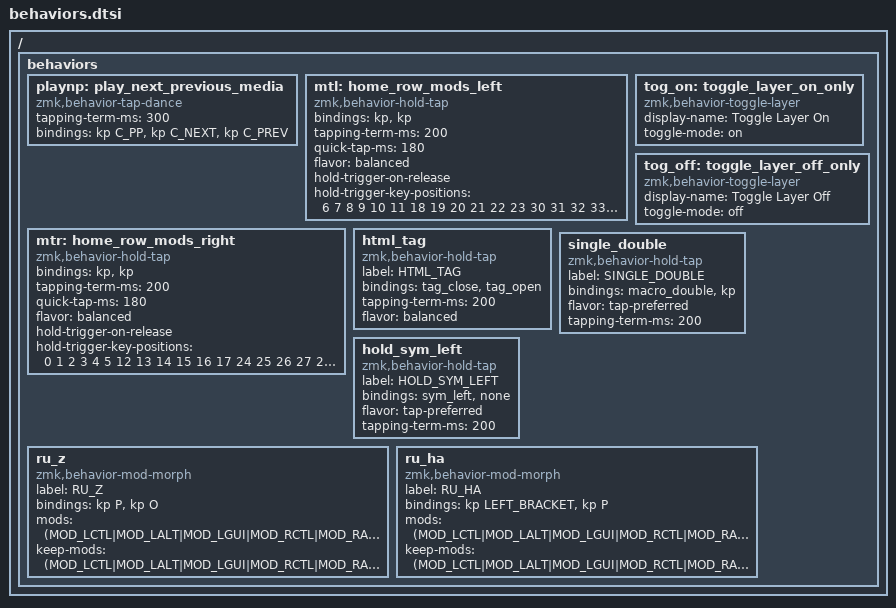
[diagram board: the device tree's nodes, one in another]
/ {
  behaviors {

    playnp: play_next_previous_media {
        compatible = "zmk,behavior-tap-dance";
        #binding-cells = <0>;
        tapping-term-ms = <300>;
        bindings = <&kp C_PP>, <&kp C_NEXT>, <&kp C_PREV>;
    };

    mtl: home_row_mods_left {
        compatible = "zmk,behavior-hold-tap";
        bindings = <&kp>, <&kp>;

        #binding-cells = <2>;
        tapping-term-ms = <200>;
        quick-tap-ms = <180>;
        flavor = "balanced";
        hold-trigger-on-release;
        hold-trigger-key-positions = <6 7 8 9 10 11 18 19 20 21 22 23 30 31 32 33 34 35 40 41 39 38 37 36 12 24>;
    };

    mtr: home_row_mods_right {
        compatible = "zmk,behavior-hold-tap";
        bindings = <&kp>, <&kp>;

        #binding-cells = <2>;
        tapping-term-ms = <200>;
        quick-tap-ms = <180>;
        flavor = "balanced";
        hold-trigger-on-release;
        hold-trigger-key-positions = <0 1 2 3 4 5 12 13 14 15 16 17 24 25 26 27 28 29 36 37 38 39 40 41>;
    };

    tog_on: toggle_layer_on_only {
        compatible = "zmk,behavior-toggle-layer";
        #binding-cells = <1>;
        display-name = "Toggle Layer On";
        toggle-mode = "on";
    };

    tog_off: toggle_layer_off_only {
        compatible = "zmk,behavior-toggle-layer";
        #binding-cells = <1>;
        display-name = "Toggle Layer Off";
        toggle-mode = "off";
    };

    html_tag: html_tag {
        compatible = "zmk,behavior-hold-tap";
        label = "HTML_TAG";
        bindings = <&tag_close>, <&tag_open>;

        #binding-cells = <2>;
        tapping-term-ms = <200>;
        flavor = "balanced";
    };

    single_double: single_double {
        compatible = "zmk,behavior-hold-tap";
        label = "SINGLE_DOUBLE";
        bindings = <&macro_double>, <&kp>;

        #binding-cells = <2>;
        flavor = "tap-preferred";
        tapping-term-ms = <200>;
    };

    hold_sym_left: hold_sym_left {
        compatible = "zmk,behavior-hold-tap";
        label = "HOLD_SYM_LEFT";
        bindings = <&sym_left>, <&none>;

        #binding-cells = <2>;
        flavor = "tap-preferred";
        tapping-term-ms = <200>;
    };

    ru_z: ru_z {
        compatible = "zmk,behavior-mod-morph";
        label = "RU_Z";
        bindings = <&kp P>, <&kp O>;

        #binding-cells = <0>;
        mods = <(MOD_LCTL|MOD_LALT|MOD_LGUI|MOD_RCTL|MOD_RALT|MOD_RGUI)>;
        keep-mods = <(MOD_LCTL|MOD_LALT|MOD_LGUI|MOD_RCTL|MOD_RALT|MOD_RGUI)>;
    };

    ru_ha: ru_ha {
        compatible = "zmk,behavior-mod-morph";
        label = "RU_HA";
        bindings = <&kp LEFT_BRACKET>, <&kp P>;

        #binding-cells = <0>;
        mods = <(MOD_LCTL|MOD_LALT|MOD_LGUI|MOD_RCTL|MOD_RALT|MOD_RGUI)>;
        keep-mods = <(MOD_LCTL|MOD_LALT|MOD_LGUI|MOD_RCTL|MOD_RALT|MOD_RGUI)>;
    };
  };
};
